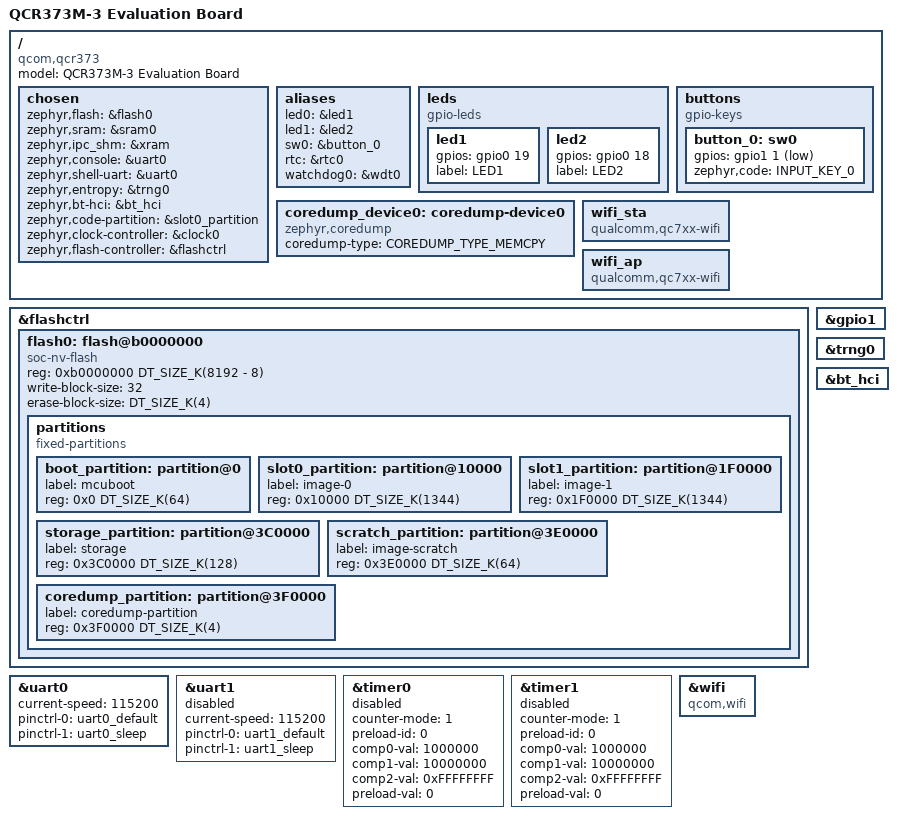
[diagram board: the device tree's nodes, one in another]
/*
 * Copyright (c) Qualcomm Technologies, Inc. and/or its subsidiaries
 * SPDX-License-Identifier: BSD-3-Clause
 */

/dts-v1/;

#include <qcom/qcr3xx/qcr3733.dtsi>
#include <zephyr/dt-bindings/input/input-event-codes.h>
#include "qcr373m3_evb-pinctrl.dtsi"

/ {
	model = "QCR373M-3 Evaluation Board";
	compatible = "qcom,qcr373";

	chosen {
		zephyr,flash = &flash0;
		zephyr,sram = &sram0;
		zephyr,ipc_shm = &xram;
		zephyr,console = &uart0;
		zephyr,shell-uart = &uart0;
		zephyr,entropy = &trng0;
		zephyr,bt-hci = &bt_hci;
		zephyr,code-partition = &slot0_partition;
		zephyr,clock-controller = &clock0;
		zephyr,flash-controller = &flashctrl;
	};

	aliases {
		led0 = &led1;
		led1 = &led2;
		sw0 = &button_0;
		rtc = &rtc0;
		watchdog0 = &wdt0;
	};

	leds {
		compatible = "gpio-leds";
		led1: led1 {
			gpios = <&gpio0 19 GPIO_ACTIVE_HIGH>;
			label = "LED1";
		};
		led2: led2 {
			gpios = <&gpio0 18 GPIO_ACTIVE_HIGH>;
			label = "LED2";
		};
	};

	buttons {
		compatible = "gpio-keys";
		button_0: sw0 {
			gpios = <&gpio1 1 (GPIO_PULL_DOWN | GPIO_ACTIVE_LOW)>;
			zephyr,code = <INPUT_KEY_0>;
		};
	};
};

/ {
	coredump_device0: coredump-device0 {
		compatible = "zephyr,coredump";
		coredump-type = "COREDUMP_TYPE_MEMCPY";
		status = "okay";
	};
};

&flashctrl {
	flash0: flash@b0000000 {
		compatible = "soc-nv-flash";
		reg = <0xb0000000 DT_SIZE_K(8192 - 8)>;
		write-block-size = <32>;
		erase-block-size = <DT_SIZE_K(4)>;
		status = "okay";

		partitions {
			compatible = "fixed-partitions";
			#address-cells = <1>;
			#size-cells = <1>;

			boot_partition: partition@0 {
				label = "mcuboot";
				reg = <0x0 DT_SIZE_K(64)>;
			};

			slot0_partition: partition@10000 {
				label = "image-0";
				reg = <0x10000 DT_SIZE_K(1344)>;
			};

			slot1_partition: partition@1F0000 {
				label = "image-1";
				reg = <0x1F0000 DT_SIZE_K(1344)>;
			};

			storage_partition: partition@3C0000 {
				label = "storage";
				reg = <0x3C0000 DT_SIZE_K(128)>;
			};

			scratch_partition: partition@3E0000 {
				label = "image-scratch";
				reg = <0x3E0000 DT_SIZE_K(64)>;
			};

			coredump_partition: partition@3F0000 {
				label = "coredump-partition";
				reg = <0x3F0000 DT_SIZE_K(4)>;
			};
		};
	};
};

&uart0 {
	status = "okay";
	current-speed = <115200>;
	pinctrl-0 = <&uart0_default>;
	pinctrl-1 = <&uart0_sleep>;
	pinctrl-names = "default", "sleep";
};

&uart1 {
	status = "disabled";
	current-speed = <115200>;
	pinctrl-0 = <&uart1_default>;
	pinctrl-1 = <&uart1_sleep>;
	pinctrl-names = "default", "sleep";
};

&gpio1 {
	status = "okay";
};

&trng0 {
	status = "okay";
};

&timer0 {
	status = "disabled";
	counter-mode = <1>;
	preload-id = <0>;
	comp0-val = <1000000>;
	comp1-val = <10000000>;
	comp2-val = <0xFFFFFFFF>;
	preload-val = <0>;
};

&timer1 {
	status = "disabled";
	counter-mode = <1>;
	preload-id = <0>;
	comp0-val = <1000000>;
	comp1-val = <10000000>;
	comp2-val = <0xFFFFFFFF>;
	preload-val = <0>;
};

&wifi {
	compatible = "qcom,wifi";
	status = "okay";
};

/ {
	wifi_sta: wifi_sta {
		compatible = "qualcomm,qc7xx-wifi";
		status = "okay";
	};
	wifi_ap: wifi_ap {
		compatible = "qualcomm,qc7xx-wifi";
		status = "okay";
	};
};

&bt_hci {
	status = "okay";
};
